# PCIE0_CORE_DBN_CFG_PCIE_CORE register map
Vendor: Texas Instruments
Registers are 32-bit, read-write, reset 0x0 unless marked. A register's access mark holds for its fields unless they carry their own. Offsets are as the file gives them; [hi:lo] are bit positions; lines under a group give offsets from that group; {n}, {i} and the like mark numbered series.

## PCIE0_CORE_DBN_CFG_PCIE_CORE (part 4 of 6)
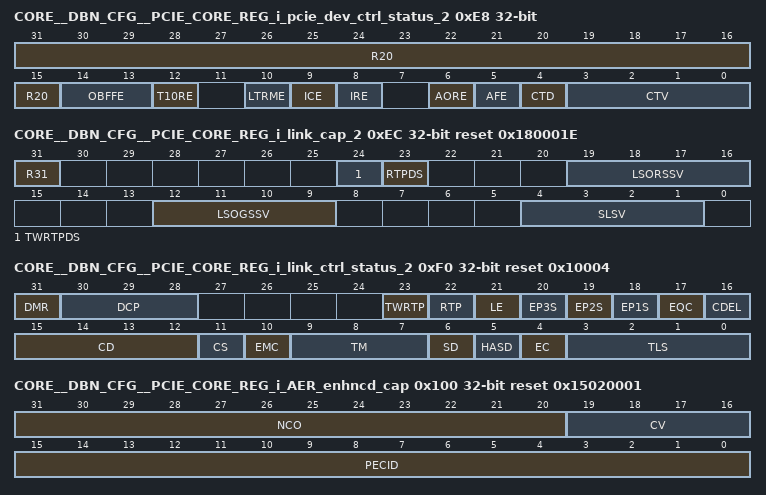
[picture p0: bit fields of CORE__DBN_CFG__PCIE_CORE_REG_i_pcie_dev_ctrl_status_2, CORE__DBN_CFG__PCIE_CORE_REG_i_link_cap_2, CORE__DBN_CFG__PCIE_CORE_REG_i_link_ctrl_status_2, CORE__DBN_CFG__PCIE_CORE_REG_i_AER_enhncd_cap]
0xE8 CORE__DBN_CFG__PCIE_CORE_REG_i_pcie_dev_ctrl_status_2 access per field
  [31:15] R20 ro
  [14:13] OBFFE rw — Enables the Optimized Buffer Flush/Fill [OBFF] capability in the device. Valid settings are 00 [disabled], 01 [Variation A], and 10 [Variation B].
  [12] T10RE ro — 10bit TAGs generation are not supported in this configuration.
  [10] LTRME rw — This must be set to 1 to enable the Latency Tolerance Reporting Mechanism. This bit is implemented only in PF 0. Its default value is 1, but can be modified from the local management bus. This bit is read-only in PF 1.
  [9] ICE rw — When this bit is 1, the RC is allowed to set the ID-based Ordering [IDO] Attribute bit in the Completions it generates.
  [8] IRE rw — When this bit is 1, the RC is allowed to set the ID-based Ordering [IDO] Attribute bit in the requests it generates.
  [6] AORE ro — This bit must be set to enable the generation of Atomic Op Requests. If the client logic attempts to send an Atomic Op when this bit is not set, logic in the Controller will nullify the TLP on its way to the link.
  [5] AFE rw — A 1 in this filed indicates that the port treats fields 7:0 of the ID as function number while converting a Type 1 config packet to type 0 config packet.
  [4] CTD rw — Setting this bit disables the Completion Timeout in the device.
  [3:0] CTV rw — Specifies the Completion Timeout value for the device. Allowable values are 0101 [sub-range 1] and 0110 [sub-range 2]. The corresponding timeout values are stored in the local management register's Completion Timeout Interval Registers 0 and 1, respectively. Value of 0 selects completion timeout from Completion-Timeout-Interval-Registers-0 in local management register.
0xEC CORE__DBN_CFG__PCIE_CORE_REG_i_link_cap_2 ro reset 0x180001E
  [31] R31 — Indicates support for the optional Device Readiness Status [DRS] capability. This capability is currently not supported in the Controller.
  [24] TWRTPDS — When set to 1b, this bit indicates that the associated Port supports detection and reporting of two Retimers presence. This bit is valid for both Downstream Ports and Upstream Ports.
  [23] RTPDS — When set to 1b, this bit indicates that the associated Port supports detection and reporting of Retimer presence. This bit is valid for both Downstream Ports and Upstream Ports.
  [19:16] LSORSSV — If this field is non-zero, it indicates that the Port, when operating at the indicated speed[s] supports SRIS and also supports receiving SKP OS at the rate defined for SRNS while running in SRIS.
  [12:9] LSOGSSV — If this field is non-zero, it indicates that the Port, when operating at the indicated speed[s] supports SRIS and also supports software control of the SKP Ordered Set transmission scheduling rate.
  [4:1] SLSV — This field indicates the supported link speeds of the Controller. For each bit, a value of 1 indicates that the corresponding link speed is supported, while a value of 0 indicates that the corresponding speed is not supported. The bits corresponding to various link speeds are: Bit 1 = Link Speed 2.5 GT/s, Bit 2 = Link Speed 5 GT/s, Bit 3 = Link Speed 8 GT/s, Bit 4 = Link Speed 16 GT/s. This field is hardwired to 0001 [2.5 GT/s] when the PCIE_GENERATION_SEL strap pins of the Controller are set to 0, 0011 [2.5 and 5 GT/s] when the strap is set to 1, and 0111 [2.5, 5, and 8 GT/s] when the strap pin is set to 10, and 1111 [2.5, 5, 8 and 16 GT/s] when the strap pin is set to 11.
0xF0 CORE__DBN_CFG__PCIE_CORE_REG_i_fc_init_delay_reg reset 0x64
  [15:0] FCINITDLY — Delay between successive sets of P, NP, CPL FC_INIT DLLP transmissions for VCx.
0xF0 CORE__DBN_CFG__PCIE_CORE_REG_i_link_ctrl_status_2 access not given reset 0x10004
  [31] DMR ro — DRS is not supported by the Controller and hence this field is not implemented.
  [30:28] DCP ro — DRS is not supported by the Controller and hence this field is not implemented.
  [23] TWRTP ro — When set to 1b, this bit indicates that two Retimers were present during the most recent Link negotiation.
  [22] RTP ro — When set to 1b, this bit indicates that a Retimer was present during the most recent Link negotiation.
  [21] LE — When the Controller [RP] receives an 8GTs equalization request from an Upstream Port the Controller internally sets this bit to 1. [i.e. when RP is in the Recovery.RcvrCfg state and receives 8 consecutive TS2 Ordered Sets with the Request Equalization bit set to 1b] The LOCAL_INTERRUPT output is also asserted if Link Equalization Request Interrupt Enable is enabled. (access R/W1TC)
  [20] EP3S ro — This bit, when set to 1, indicates that the Phase 3 of the Transmitter Equalization procedure has completed successfully. STICKY
  [19] EP2S ro — This bit, when set to 1, indicates that the Phase 2 of the Transmitter Equalization procedure has completed successfully. STICKY
  [18] EP1S ro — This bit, when set to 1, indicates that the Phase 1 of the Transmitter Equalization procedure has completed successfully. STICKY
  [17] EQC ro — This bit, when set to 1, indicates that the Transmitter Equalization procedure has completed. STICKY
  [16] CDEL ro — This status bit indicates the current operating de-emphasis level of the transmitter [0 = -6dB, 1 = -3.5dB].
  [15:12] CD rw — This bit sets the de-emphasis level [for 5 GT/s operation] or the Transmitter Preset level [for 8 GT/s or 16 GT/s operation] when the LTSSM enters the Polling.Compliance state because of software setting the Enter Compliance bit in this register. It is used only when the link is running at 5 GT/s or 8 GT/s or 16 GT/s. At 5 GT/s, the only valid setting are 0 [-6 dB] and 1 [-3.5 dB]. STICKY
  [11] CS rw — When this bit is set to 1, the device will transmit SKP ordered sets between compliance patterns. STICKY
  [10] EMC rw — This field is intended for debug and compliance testing purposes only. If this bit is set to 1, the device will transmit the Modified Compliance Pattern when the LTSSM enters the Polling.Compliance substate. STICKY
  [9:7] TM rw — This field is intended for debug and compliance testing purposes only. It controls the non-deemphasized voltage level at the transmitter outputs. Its encodings are: 000 = Normal operating range, 001 = 800 - 1200 mV for full swing and 400 - 700 mV for half swing, 010 - 111 = See PCI Express Base Specification 2.0. This field is reset to 0 when th LTSSM enters the Polling.Configuration substate during link training. STICKY.
  [6] SD rw — This bit selects the de-emphasis level when the Controller is operating at 5 GT/s [0 = -6 dB, 1 = -3.5 dB].
  [5] HASD rw — When this bit is set, the LTSSM is prevented from changing the operating speed of the link, other than reducing the speed to correct unreliable operation of the link. STICKY
  [4] EC rw — This bit is used to force the Endpoint device to enter the Compliance mode. Software sets this bit to 1 and initiates a hot reset to force the device into the Compliance mode. The target speed for the Compliance mode is determined by the Target Link Speed field of this register. STICKY.
  [3:0] TLS rw — This field sets the target speed when the software forces the link into Compliance mode by setting the Enter Compliance bit in this register [0001 = 2.5 GT/s, 0010 = 5 GT/s, 0100 = 8 GT/s,1000 = 16 GT/s]. The default value of this field is 0001 [2.5 GT/s] when the PCIE_GENERATION_SEL[1:0] strap pins of the Controller are set to 0, 0010 [5 GT/s] when the strap is set to 1, and 0011 [8 GT/s] when the strap pin is set to 10 , and 0100 [16 GT/s] when the strap pin is set to 11. STICKY.
{0x100+4i} CORE__DBN_CFG__PCIE_CORE_REG_i_shdw_hdr_log_{i}_reg (i=0..3)
  [31:0] SHDW_HDR_LOG_{i} — The value here will be reflected in the target function's header log register when f/w sets any bit in the the shadow error register. If the header log is already set in the function's AER space, the value here may not get written and a header log overflow bit would get set. This register holds [{32i+31}:{32i}] value of the TLP header.
0x100 CORE__DBN_CFG__PCIE_CORE_REG_i_AER_enhncd_cap ro reset 0x15020001
  [31:20] NCO — Indicates offset to the next PCI Express capability structure. The default next pointer value is dynamic and is dependent on whether the strap or LMI bits are set.
  [19:16] CV — Specifies the SIG assigned value for the version of the capability structure. This field is set by default to 4'h2.
  [15:0] PECID — This field is hardwired to the Capability ID assigned by PCI SIG to the PCI Express AER Extended Capability Structure [0001 hex].
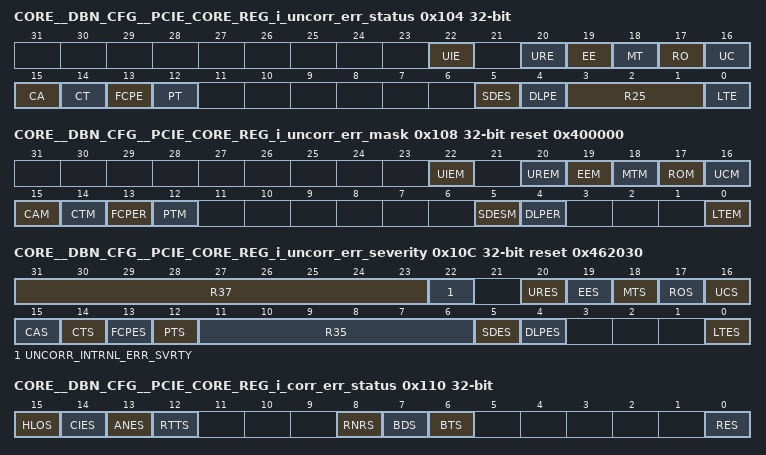
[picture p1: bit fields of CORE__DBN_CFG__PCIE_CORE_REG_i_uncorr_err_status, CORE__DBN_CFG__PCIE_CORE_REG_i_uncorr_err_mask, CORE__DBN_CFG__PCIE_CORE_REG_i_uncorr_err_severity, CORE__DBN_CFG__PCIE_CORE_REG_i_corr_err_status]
0x104 CORE__DBN_CFG__PCIE_CORE_REG_i_uncorr_err_status access not given
  [22] UIE — This bit is set when the Controller has detected an internal uncorrectable error [HAL parity error or an uncorrectable ECC error while reading from any of the RAMs]. This bit is also set in response to the client signaling an internal error through the input UNCORRECTABLE_ERROR_IN. This error is considered fatal by default. (access R/W1TC)
  [20] URE — This bit is set when the Controller has received a request from the link that it does not support. This error is not Function-specific. This error is considered non-fatal by default, except for the special case outlined in PCI Express Base Specification 2.0. The header of the received request that caused the error is logged in the Header Log Registers. (access R/W1TC)
  [19] EE — This bit is set when the Controller has detected an ECRC error in a received TLP. (access R/W1TC)
  [18] MT — This bit is set when the Controller receives a malformed TLP from the link. This error is considered fatal by default. The header of the received TLP with error is logged in the Header Log Registers. (access R/W1TC)
  [17] RO — This bit is set when the Controller receives a TLP in violation of the receive credit currently available. (access R/W1TC)
  [16] UC — This bit is set when the Controller has received an unexpected Completion packet from the link. (access R/W1TC)
  [15] CA — This bit is set when the Controller has returned the Completer Abort [CA] status to a request received from the link. This error is considered non-fatal by default, except for the special cases outlined in PCI Express Base Specification 2.0. The header of the received request that caused the error is logged in the Header Log Registers. (access R/W1TC)
  [14] CT — This bit is set when the completion timer associated with an outstanding request times out. This error is considered non-fatal by default. (access R/W1TC)
  [13] FCPE — This bit is set when certain violations of the flow control protocol are detected by the Controller. (access R/W1TC)
  [12] PT — This bit is set when the Controller receives a poisoned TLP from the link. This error is considered non-fatal by default. The header of the received TLP with error is logged in the Header Log Registers. (access R/W1TC)
  [5] SDES — This error status indicates Link up to Link down event. So Status bit is set upon LINK_DOWN_RESET_OUT event. This field is applicable to RC only and not for EP as per PCIE-spec. (access R/W1TC)
  [4] DLPE — This bit is set when the Controller receives an Ack or Nak DLLP whose sequence does not correspond to that of an unacknowledged TLP or that of the last acknowledged TLP [for details, refer to the PCI Express Base Specifications]. (access R/W1TC)
  [3:1] R25 ro
  [0] LTE — This error indicates that link training is not successful and transition back to detect state. This Status bit is set on any LTSSM transition from Configuration to Detect or Recovery to Detect. This field is applicable to RC only and not for EP as per PCIE-spec. (access R/W1TC)
0x108 CORE__DBN_CFG__PCIE_CORE_REG_i_uncorr_err_mask reset 0x400000
  [22] UIEM — This bit is set to mask the reporting of internal errors. STICKY.
  [20] UREM — This bit is set to mask the reporting of unexpected requests received from the link. STICKY.
  [19] EEM — This bit is set to mask the reporting of ECRC errors. STICKY.
  [18] MTM — This bit is set to mask the reporting of malformed TLPs received from the link. STICKY.
  [17] ROM — This bit is set to mask the reporting of violations of receive credit. STICKY.
  [16] UCM — This bit is set to mask the reporting of unexpected Completions received by the Controller. STICKY.
  [15] CAM — This bit is set to mask the reporting of the Controller sending a Completer Abort. STICKY.
  [14] CTM — This bit is set to mask the reporting of Completion Timeouts. STICKY.
  [13] FCPER — This bit is set to mask the reporting of Flow Control Protocol Errors. STICKY.
  [12] PTM — This bit is set to mask the reporting of a Poisoned TLP. STICKY.
  [5] SDESM — This bit is set to mask the reporting of Surprise Down Error Status Mask. STICKY. This field is applicable to RC only and not for EP as per PCIE-spec.
  [4] DLPER — This bit is set to mask the reporting of Data Link Protocol Errors. STICKY.
  [0] LTEM — This bit is set to mask the reporting of Link Training Error Mask. STICKY. This field is applicable to RC only and not for EP as per PCIE-spec.
0x10C CORE__DBN_CFG__PCIE_CORE_REG_i_uncorr_err_severity access per field reset 0x462030
  [31:23] R37 ro
  [22] UNCORR_INTRNL_ERR_SVRTY rw — Severity of internal errors [0 = Non-Fatal, 1 = Fatal].
  [20] URES rw — Severity of unexpected requests received from the link [0 = Non-Fatal, 1 = Fatal]. STICKY.
  [19] EES rw — Severity of ECRC errors [0 = Non-Fatal, 1 = Fatal]. STICKY.
  [18] MTS rw — Severity of malformed TLPs received from the link [0 = Non-Fatal, 1 = Fatal]. STICKY.
  [17] ROS rw — Severity of receive credit violations [0 = Non-Fatal, 1 = Fatal]. STICKY.
  [16] UCS rw — Severity of unexpected Completions received by the Controller [0 = Non-Fatal, 1 = Fatal]. STICKY.
  [15] CAS rw — Severity of sending a Completer Abort [0 = Non-Fatal, 1 = Fatal]. STICKY.
  [14] CTS rw — Severity of Completion Timeouts [0 = Non-Fatal, 1 = Fatal]. STICKY.
  [13] FCPES rw — Severity of a Flow Control Protocol Error [0 = Non-Fatal, 1 = Fatal]. STICKY.
  [12] PTS rw — Severity of a Poisoned TLP error [0 = Non-Fatal, 1 = Fatal]. STICKY.
  [11:6] R35 ro
  [5] SDES rw — surprise down error severity [0 = Non-Fatal, 1 = Fatal]. STICKY. This field is applicable to RC only and not for EP as per PCIE-spec.
  [4] DLPES rw — Severity of Data Link Protocol Errors [0 = Non-Fatal, 1 = Fatal]. STICKY.
  [0] LTES rw — Severity of Link Training Error [0 = Non-Fatal, 1 = Fatal]. STICKY. This field is applicable to RC only and not for EP as per PCIE-spec.
0x110 CORE__DBN_CFG__PCIE_CORE_REG_i_shdw_func_num_reg
  [7:0] SHDW_FUNC_NUM — The value here will be the target function number when f/w sets any bit in the shadow error register.
0x110 CORE__DBN_CFG__PCIE_CORE_REG_i_corr_err_status access not given
  [15] HLOS — This bit is set on a Header Log Register overflow, that is, when the header could not be logged in the Header Log Register because it is occupied by a previous header. (access R/W1TC)
  [14] CIES — This bit is set when the Controller has detected an internal correctable error condition [a correctable ECC error while reading from any of the RAMs]. This bit is also set in response to the client signaling an internal error through the input CORRECTABLE_ERROR_IN. (access R/W1TC)
  [13] ANES — This bit is set when an uncorrectable error occurs, which is determined to belong to one of the special cases described in the PCI Express Base Specification 2.0. This causes the Controller to assert the CORRECTABLE_ERROR_OUT output in place of NON_FATAL_ERROR_OUT. (access R/W1TC)
  [12] RTTS — This bit is set when the replay timer in the Data Link Layer of the Controller times out, causing the Controller to re-transmit a TLP. (access R/W1TC)
  [8] RNRS — This bit is set when the replay count rolls over after three re-transmissions of a TLP at the Data Link Layer of the Controller. (access R/W1TC)
  [7] BDS — This bit is set when an LCRC error is detected in a received DLLP, and no errors were detected by the Physical Layer. (access R/W1TC)
  [6] BTS — This bit is set when an error is detected in a received TLP by the Data Link Layer of the Controller the conditions causing this error are [1] an LCRC error, [2] the packet terminates with EDB symbol, but its LCRC field does not equal the inverted value of the calculated CRC. (access R/W1TC)
  [0] RES — This bit is set when an error is detected in the receive side of the Physical Layer of the Controller [e.g. an 8b10b decode error]. (access R/W1TC)
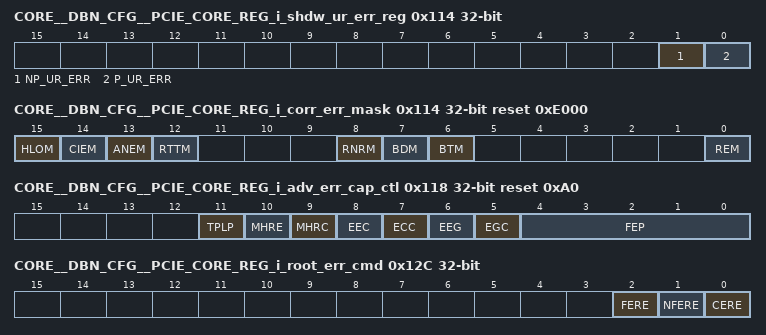
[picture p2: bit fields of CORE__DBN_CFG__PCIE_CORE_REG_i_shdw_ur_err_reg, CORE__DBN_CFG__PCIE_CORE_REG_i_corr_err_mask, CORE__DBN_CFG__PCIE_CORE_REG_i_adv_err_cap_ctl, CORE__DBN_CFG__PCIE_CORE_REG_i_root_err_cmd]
0x114 CORE__DBN_CFG__PCIE_CORE_REG_i_shdw_ur_err_reg wo
  [1] NP_UR_ERR — If this bit is set, the corresponding non-posted UR error bits will be set in the AER and device status registers of the target function.
  [0] P_UR_ERR — If this bit is set, the corresponding posted UR error bits will be set in the AER and device status registers of the target function.
0x114 CORE__DBN_CFG__PCIE_CORE_REG_i_corr_err_mask reset 0xE000
  [15] HLOM — This bit, when set, masks the reporting of an error in response to a Header Log register overflow. STICKY.
  [14] CIEM — This bit, when set, masks the reporting of an error in response to a corrected internal error condition. STICKY.
  [13] ANEM — This bit, when set, masks the reporting of an error in response to an uncorrectable error occurence, which is determined to belong to one of the special cases in the PCI Express Base Specification 2.0. STICKY.
  [12] RTTM — This bit, when set, masks the reporting of an error in response to a Replay Timer timeout event. STICKY.
  [8] RNRM — This bit, when set, masks the reporting of an error in response to a Replay Number Rollover event. STICKY.
  [7] BDM — This bit, when set, masks the reporting of an error in response to a 'Bad DLLP' received. STICKY.
  [6] BTM — This bit,when set, masks the reporting of an error in response to a 'Bad TLP' received. STICKY.
  [0] REM — This bit, when set, masks the reporting of Physical Layer errors. STICKY.
0x118 CORE__DBN_CFG__PCIE_CORE_REG_i_adv_err_cap_ctl access per field reset 0xA0
  [11] TPLP ro — If Set and the First Error Pointer is valid, indicates that the TLP Prefix Log register contains valid information. If Clear or if First Error Pointer is invalid, the TLP Prefix Log register is undefined. Default value of this bit is 0. This bit is RsvdP if the End-End TLP Prefix Supported bit is CIf Set and the First Error Pointer is valid, indicates that the TLP Prefix Log register contains valid information. If Clear or if First Error Pointer is invalid, the TLP Prefix Log register is undefined.
  [10] MHRE ro — Setting this bit enables the RC to log multiple error headers in its Header Log Registers. It is hardwired to 0.
  [9] MHRC ro — This bit is set when the RC has the capability to log more than one error header in its Header Log Registers. It is hardwired to 0.
  [8] EEC rw — Setting this bit enables ECRC checking on the receive side of the Controller. This bit is writable from the local management bus. STICKY.
  [7] ECC ro — This read-only bit indicates to the software that the device is capable of checking ECRC in packets received from the link.
  [6] EEG rw — Setting this bit enables the ECRC generation on the transmit side of the Controller. This bit is writable from the local management bus. STICKY.
  [5] EGC ro — This read-only bit indicates to the software that the device is capable of generating ECRC in packets transmitted on the link.
  [4:0] FEP ro — This is a 5-bit pointer to the bit position in the Uncorrectable Error Status Register corresponding to the error that was detected first. When there are multiple bits set in the Uncorrectable Error Status Register, this field informs the software which error was observed first. To prevent the field from being overwritten before the software is able to read it, this field is not updated while the status bit it points to in the Uncorrectable Error Status Register remains set. After the software clears this status bit, a subsequent error condition that sets any bit in the Uncorrectable Error Status Register will update the First Error Pointer. Any uncorrectable error type, including the special cases where the error is reported using an ERR_COR message, will set the First Error Pointer [assuming the software has reset the error pointed by it in the Uncorrectable Error Status Register]. STICKY.
0x11C CORE__DBN_CFG__PCIE_CORE_REG_i_hdr_log_0 ro
  [31:0] HD0 — First Dword of captured TLP header. STICKY.
0x120 CORE__DBN_CFG__PCIE_CORE_REG_i_hdr_log_1 ro
  [31:0] HD1 — Second Dword of captured TLP header. STICKY.
0x124 CORE__DBN_CFG__PCIE_CORE_REG_i_hdr_log_2 ro
  [31:0] HD2 — Third Dword of captured TLP header. STICKY.
0x128 CORE__DBN_CFG__PCIE_CORE_REG_i_hdr_log_3 ro
  [31:0] HD3 — Fourth Dword of captured TLP header. STICKY.
0x12C CORE__DBN_CFG__PCIE_CORE_REG_i_root_err_cmd
  [2] FERE — If this bit is set, the Controller will active its FATAL_ERROR_OUT output in response to an error message received from the link.
  [1] NFERE — If this bit is set, the Controller will active its NON_FATAL_ERROR_OUT output in response to an error message received from the link.
  [0] CERE — If this bit is set, the Controller will active its CORRECTABLE_ERROR_OUT output in response to an error message received from the link.
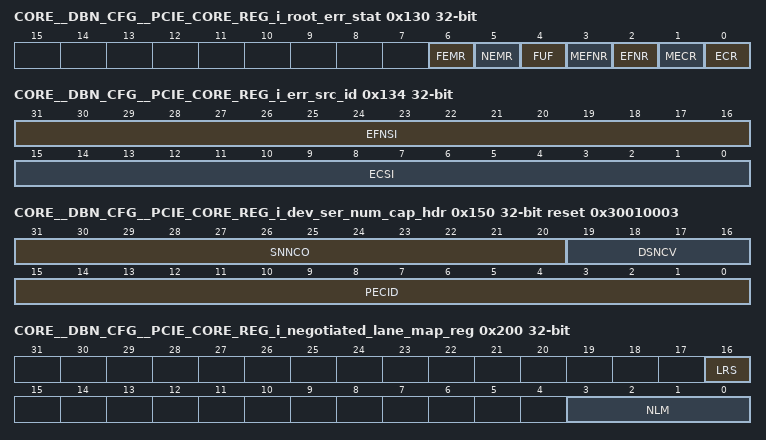
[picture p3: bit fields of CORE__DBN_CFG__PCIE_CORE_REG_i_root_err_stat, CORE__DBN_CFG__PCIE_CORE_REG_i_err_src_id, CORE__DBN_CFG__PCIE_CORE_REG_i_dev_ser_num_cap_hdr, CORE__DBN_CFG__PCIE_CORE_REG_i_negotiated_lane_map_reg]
0x130 CORE__DBN_CFG__PCIE_CORE_REG_i_root_err_stat access not given
  [6] FEMR — This bit, when set, indicates that the RC has received one or more Fatal error messages from the link. STICKY (access R/W1TC)
  [5] NEMR — This bit, when set, indicates that the RC has received one or more Non-Fatal error messages from the link. STICKY (access R/W1TC)
  [4] FUF — This bit, when set, indicates that the first Uncorrectable error message received was for a Fatal error. STICKY (access R/W1TC)
  [3] MEFNR — This bit is set when the RC receives either a Fatal or Non-Fatal error message from the link, and the ERR_FATAL/NONFATAL Received bit is already set. STICKY (access R/W1TC)
  [2] EFNR — This bit is set when the RC receives either a Fatal or Non-Fatal error message from the link. STICKY (access R/W1TC)
  [1] MECR — This bit is set when the RC receives a Correctable error message from the link, if the ERR_COR received bit is already set. STICKY (access R/W1TC)
  [0] ECR — This bit is set when the RC receives a Correctable error message from the link. STICKY (access R/W1TC)
0x134 CORE__DBN_CFG__PCIE_CORE_REG_i_err_src_id ro
  [31:16] EFNSI — This field captures and stores the Requester ID from an ERR_FATAL or ERROR_NONFATAL message received by the RC, if the ERR_FATAL or NONFATAL Received bit was not set at the time the message was received. STICKY
  [15:0] ECSI — This field captures and stores the Requester ID from an ERR_COR message received by the RC, if the ERR_COR bit was not set at the time the message was received. STICKY
0x138 CORE__DBN_CFG__PCIE_CORE_REG_i_tlp_pre_log_0 ro
  [31:0] HD1 — First TLP Prefix of captured TLP STICKY.
0x140 CORE__DBN_CFG__PCIE_CORE_REG_i_pm_clk_frequency_reg reset 0x19
  [7:0] PMCLKFRQ — This field specifies the PM_CLK Frequency selected. The encoding is described below: 000000: Reserved 000001: Reserved 000010: PM_CLK is 2 MHz 000011: PM_CLK is 3 MHz 000100: PM_CLK is 4 MHz 000101: PM_CLK is 5 MHz .. 111010: PM_CLK is 58 MHz 111011: PM_CLK is 59 MHz 111100: PM_CLK is 60 MHz 111101 : Reserved 111110 : Reserved 111111 : Reserved .
{0x140+4i} CORE__DBN_CFG__PCIE_CORE_REG_i_debug_dllp_count_gen{i}_reg ro (i=1..4)
  [31:0] DLLPCNT{i} — Reflects the total number of DLLPs received by the Controller at GEN{i} speed.
0x150 CORE__DBN_CFG__PCIE_CORE_REG_i_dev_ser_num_cap_hdr ro reset 0x30010003
  [31:20] SNNCO — Indicates offset to the next PCI Express capability structure. The default next pointer value is dynamic and is dependent on whether the strap or LMI bits are set.
  [19:16] DSNCV — Specifies the SIG assigned value for the version of the capability structure. This field is set by default to 1, but can be modified from the local management bus by writing into Function 0 from the local management bus.
  [15:0] PECID — This field is hardwired to the Capability ID assigned by PCI SIG to the PCI Express Device Serial Number Capability [0001 hex].
0x154 CORE__DBN_CFG__PCIE_CORE_REG_i_dev_ser_num_0 ro
  [31:0] DSND0 — This field contains the first 32 bits of the device's serial number. This field can be written from the APB bus by setting [21] bit high of the pcie_mgmt_APB_ADDR during a local management register write.
0x158 CORE__DBN_CFG__PCIE_CORE_REG_i_vendor_defined_message_tag_reg
  [7:0] VDMTAG — The Controller will use the tag programed in this register for all Outbound Vendor Defined Messages.
0x158 CORE__DBN_CFG__PCIE_CORE_REG_i_dev_ser_num_1 ro
  [31:0] DSND1 — This field contains the last 32 bits of the device's serial number. This field can be written from the APB bus by setting [21] bit high of the pcie_mgmt_APB_ADDR during a local management register write.
0x200 CORE__DBN_CFG__PCIE_CORE_REG_i_negotiated_lane_map_reg ro
  [16] LRS — This bit set by the Controller at the end of link training if the LTSSM had to reverse the lane numbers to form the link.
  [3:0] NLM — Bit i of this field is set to 1 at the end of link training if Lane i is part of the PCIe link. The value of this field is valid only when the link is in L0 or L0s states.
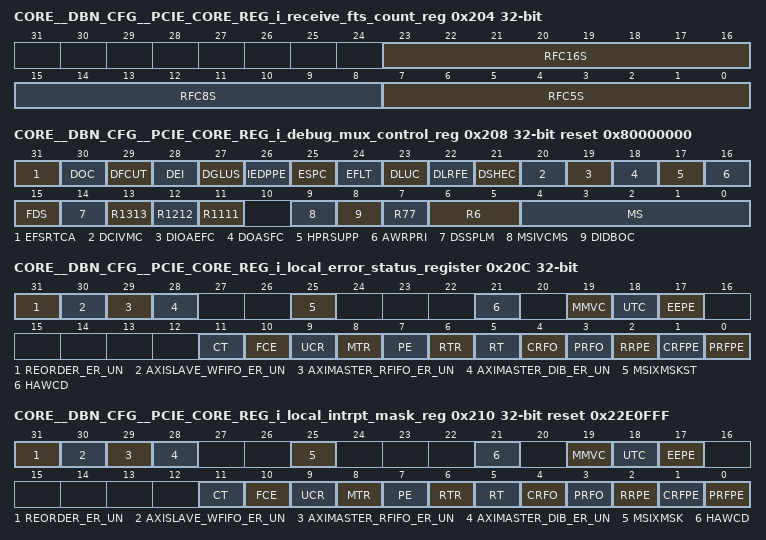
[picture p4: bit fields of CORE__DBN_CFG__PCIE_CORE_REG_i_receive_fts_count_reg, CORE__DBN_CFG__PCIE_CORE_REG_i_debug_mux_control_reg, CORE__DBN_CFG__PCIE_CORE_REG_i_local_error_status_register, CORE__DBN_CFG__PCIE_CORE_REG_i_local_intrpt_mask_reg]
0x204 CORE__DBN_CFG__PCIE_CORE_REG_i_receive_fts_count_reg ro
  [23:16] RFC16S — FTS count received from the other side during link training for use at the 16 GT/s link speed. The Controller transmits this many FTS sequences while exiting the L0S state, when operating at the 16 GT/s speed.
  [15:8] RFC8S — FTS count received from the other side during link training for use at the 8 GT/s link speed. The Controller transmits this many FTS sequences while exiting the L0S state, when operating at the 8 GT/s speed.
  [7:0] RFC5S — FTS count received from the other side during link training for use at the 5 GT/s link speed. The Controller transmits this many FTS sequences while exiting the L0S state, when operating at the 5 GT/s speed.
0x208 CORE__DBN_CFG__PCIE_CORE_REG_i_debug_mux_control_reg access per field reset 0x80000000
  [31] EFSRTCA rw — Setting this bit to 0 causes all the enabled Functions to report an error when a Type-1 configuration access is received by the Controller, targeted at any Function. Setting it to 1 limits the error reporting to the type-0 Function whose number matches with the Function number specified in the request. If the Function number in the request refers to an unimplemented or disabled Function, all enabled Functions report the error regardless of the setting of this bit.
  [30] DOC rw — Setting this bit to 1 disables the ordering check in the Controller between Completions and Posted requests received from the link.
  [29] DFCUT rw — When this bit is 0, the Controller will time out and re-train the link when no Flow Control Update DLLPs are received from the link within an interval of 128 us. Setting this bit to 1 disables this timeout. When the advertised receive credit of the link partner is infinity for the header and payload of all credit types, this timeout is always suppressed. The setting of this bit has no effect in this case. This bit should not be set during normal operation, but is useful for testing.
  [28] DEI rw — Setting this bit to 1 disables the inferring of electrical idle in the L0 state. Electrical idle is inferred when no flow control updates and no SKP sequences are received within an interval of 128 us. This bit should not be set during normal operation, but is useful for testing.
  [27] DGLUS rw — Setting this bit to 1 disables the update of the LFSRs in the Gen3 descramblers of the Controller, from the values received in SKP sequences. This bit should not be set during normal operation, but is useful for testing.
  [26] IEDPPE rw — When set to 1, this bit inverts the parity bits generated by the Controller for end-to-end data protection. This will result in the inversion of parity bits for data payloads delivered through the HAL Target Interface request descriptor. This bit is to be used for diagnostics only, and should not be set during normal operation.
  [25] ESPC rw — When this bit is set to 1, the Controller will capture the Slot Power Limit Value and Slot Power Limit Scale parameters from a Set_Slot_Power_Limit message received in the Device Capabilities Register. When this bit is 0, the capture is disabled. This bit is valid only when the Controller is configured as an EndPoint. It has no effect when the Controller is a Root Complex.
  [24] EFLT rw — This bit is provided to shorten the link training time to facilitate fast simulation of the design, especially at the gate level. Enabling this bit has the following effects: 1. The 1 ms, 2 ms, 12 ms, 24 ms, 32 ms and 48 ms timeout intervals in the LTSSM are shortened by a factor of 500. 2. In the Polling.Active state of the LTSSM, only 16 training sequences are required to be transmitted [Instead of 1024] to make the transition to the Configuration state. This bit should not be set during normal operation of the Controller.
  [23] DLUC rw — The user may set this bit to turn off the link upconfigure capability of the Controller. Setting this bit prevents the Controller from advertising the link upconfigure capability in training sequences transmitted in the Configuration.Complete state. In addition, setting this bit causes the Controller to put the unused lanes into Turn Off mode. When disable_link_upconfigure_capability==1: Controller drives PIPE_TX_ELEC_IDLE==1 AND PIPE_TX_COMPLIANCE==1 for the Unused upper lanes. The Unused upper lanes are put into Turn Off mode by the PHY as per PIPE specification. When disable_link_upconfigure_capability==0: Controller drives PIPE_TX_ELEC_IDLE==1 AND PIPE_TX_COMPLIANCE==0 for the Unused upper lanes. The Unused upper lanes are put into Electrical Idle by the PHY.
  [22] DLRFE rw — When this bit is 1, the Controller will not transition its LTSSM into the Recovery state when it detects a Framing Error at 8 GT/s or 16 GT/s speed [as defined in Section 4.2.2.3.3 of the PCIe Base Specification 3.0. This bit must normally be set to 0 so that a Framing Error will cause the LTSSM to enter Recovery. The setting of this bit has no effect on the operation of the Controller at 2.5 and 5 GT/s speeds.
  [21] DSHEC rw — When this bit is 0, the Controller will signal a framing error if it detects a sync header error in the received blocks at 8 GT/s or 16 GT/s speed [A 00 or 11 binary setting of the sync header on the received blocks in any lane constitutes a framing error]. Setting this bit to 1 suppresses this error check. This bit should normally be set to 0, as the sync header check is mandatory in the PCIe 3.0 Specifications.
  [20] DCIVMC rw — When this bit is 1, the Controller will not check for invalid message codes. This bit should normally set to 0, as the invalid message code checking is mandatory in the PCIe 3.0 specifications.
  [19] DIOAEFC rw — When this bit is 1, the Controller will not check for illegal OS after EDS as part of Gen3 Framing Error Checks. This bit should normally set to 0, as this is a mandatory Gen3 Framing Error check in the PCIe 3.0 specifications.
  [18] DOASFC rw — When this bit is 1, the Controller will not check for OS after SKIP OS as part of Gen3 Framing Error Checks. This bit should normally set to 0, as this is a mandatory Gen3 Framing Error check in the PCIe 3.0 specifications.
  [17] HPRSUPP rw — When this bit is 1, data path parity check is disabled on the TX side of the Controller.
  [16] AWRPRI rw — When this bit is 1, the AXI bridge places a write request on the HAL Master interface in preference over a read request if both AXI write and AXI read requests are available to be asserted on the same clock cycle.
  [15] FDS rw — Disable Scrambling/Descrambling in Gen1/Gen2.
  [14] DSSPLM rw — Disable sending Set Slot Power Limit Message if the Slot Capabilitied register is configured
  [13] R1313 ro
  [12] R1212 ro
  [11] R1111 rw — When this bit is 1, Disable Client TX MUX Completion and PNP request arbitartion,roundrobin priority logic added to prevent PNP requests from starving when completions are present
  [9] MSIVCMS rw — Sets the mode of generating MSI_VECTOR_COUNT output for all functions. 0 - MSI_VECTOR_COUNT always outputs the configured value of MSI Multiple Message Enable[2:0] register. 1 - MSI_VECTOR_COUNT outputs the lesser of the MSI Multiple Message Enable[2:0] and MSI Multiple Message Capable[2:0] This mode can be used to handle any programming error form the Host software.
  [8] DIDBOC rw — Setting this bit to 1 disables the ID Based Ordering check in the Controller between Completions and Posted requests received from the link.
  [7] R77 rw — This bit should be set to 0 for backward compatibility.
  [6:5] R6 ro
  [4:0] MS rw — Bits 4:3 select the module and bits 2:0 select the group of signals within the module that are driven on the debug bus. The assignments of signals on the debug outputs of the Controller are given in Appendix B.
0x20C CORE__DBN_CFG__PCIE_CORE_REG_i_local_error_status_register access not given
  [31] REORDER_ER_UN — This indicates an uncorrectbale axi slave reorder ram parity/ecc error (access R/W1TC)
  [30] AXISLAVE_WFIFO_ER_UN — This indicates an uncorrectbale axi slave write fifo ram parity/ecc error (access R/W1TC)
  [29] AXIMASTER_RFIFO_ER_UN — This indicates an uncorrectbale axi master write fifo ram parity/ecc error (access R/W1TC)
  [28] AXIMASTER_DIB_ER_UN — This indicates an uncorrectbale axi slave write fifo ram parity/ecc error (access R/W1TC)
  [25] MSIXMSKST — This interrupt status bit is used when MSIX Function Mask Enhanced Interrupt Enable bit is set to 0 by the User. This status bit indicates that the MSIX Function Mask bit of any function, PF or VF, was programmed or configured by Local Firmware Or Host SW. (access R/W1TC)
  [21] HAWCD — This interrupt status bit indicates that the Host toggled the Hardware Autonomous Width Change bit in the Link Control Register through a Config Write. Upon this interrupt, the Client firmware must read the Link Control Register to check the value set by Host in the Hardware Autonomous Width Change bit. The Host Software may disable autonomous width change by setting Hardware Autonomous Width Disable bit in the Link Control register. If disabled by the Host and if the Endpoint firmware had initiated an autonomous width downsizing prior to this interrupt, then the local Client firmware is responsible to upconfigure the Link to go to its full functional width by initiating the link_upconfigure_retrain_link within 1 ms of this interrupt. (access R/W1TC)
  [19] MMVC — This status bit is set whenever the MSI mask register value in the MSI capability register changes value in ANY of the functions in the controller (access R/W1TC)
  [18] UTC — Unmapped TC error. (access R/W1TC)
  [17] EEPE — The Controller detected an End to End Parity Error (access R/W1TC)
  [11] CT — A request timed out waiting for completion. (access R/W1TC)
  [10] FCE — An error was observed in the flow control advertisements from the other side. (access R/W1TC)
  [9] UCR — Unexpected Completion received from the link. (access R/W1TC)
  [8] MTR — Malformed TLP received from the link. (access R/W1TC)
  [7] PE — Phy error detected on receive side. This bit is set when an error is detected in the receive side of the Physical Layer of the Controller [e.g. a bit error or coding violation]. This bit is set upon any of the following errors: [1] PHY reported 8B10B error, Disparity Error, Elastic Buffer Overflow Error, Underflow Error [2] GEN3 TLP, DLLP Framing Errors [3] OS Block Received Without EDS [4] Data Block Received After EDS [5] Illegal OS Block After EDS [6] OS Block Received After SKIP OS [7] OS Block Received After SDS [8] Sync Header Error [9] Loss of Gen3 Block Alignment This error is not Function-specific.. (access R/W1TC)
  [6] RTR — Replay timer rolled over after 4 transmissions of the same TLP. (access R/W1TC)
  [5] RT — Replay timer timed out (access R/W1TC)
  [4] CRFO — Overflow occurred in the Completion Receive FIFO. (access R/W1TC)
  [3] PRFO — Overflow occurred in the PNP Receive FIFO. (access R/W1TC)
  [2] RRPE — Parity error detected while reading from Replay Buffer RAM. (access R/W1TC)
  [1] CRFPE — Parity error detected while reading from the Completion Receive FIFO RAM. (access R/W1TC)
  [0] PRFPE — Parity error detected while reading from the PNP Receive FIFO RAM. (access R/W1TC)
0x210 CORE__DBN_CFG__PCIE_CORE_REG_i_local_intrpt_mask_reg reset 0x22E0FFF
  [31] REORDER_ER_UN — mask for uncorrectbale axi slave reorder ram parity/ecc error
  [30] AXISLAVE_WFIFO_ER_UN — mask for uncorrectbale axi slave write fifo ram parity/ecc error
  [29] AXIMASTER_RFIFO_ER_UN — mask for uncorrectbale axi master write fifo ram parity/ecc error
  [28] AXIMASTER_DIB_ER_UN — mask for uncorrectbale axi slave write fifo ram parity/ecc error
  [25] MSIXMSK — This bit is used to mask interrupt that indicates that the MSIX Function Mask bit of any function, PF or VF, was programmed or configured by Local Firmware Or Host SW.
  [21] HAWCD — This bit is used to mask interrupt that indicates that the Host toggled the Hardware Autonomous Width Change in the Endpoint Link Control Register through a Config Write.
  [19] MMVC — MSI mask register value in the MSI capability register changes value in ANY of the functions in the controller
  [18] UTC — Unmapped TC error
  [17] EEPE — The Controller detected an End to End Parity Error
  [11] CT — A request timed out waiting for completion.
  [10] FCE — An error was observed in the flow control advertisements from the other side.
  [9] UCR — Unexpected Completion received from the link.
  [8] MTR — Malformed TLP received from the link.
  [7] PE — Phy error detected on receive side.
  [6] RTR — Replay timer rolled over after 4 transmissions of the same TLP.
  [5] RT — Replay timer timed out
  [4] CRFO — Overflow occurred in the Completion Receive FIFO.
  [3] PRFO — Overflow occurred in the PNP Receive FIFO.
  [2] RRPE — Parity error detected while reading from Replay Buffer RAM.
  [1] CRFPE — Parity error detected while reading from the Completion Receive FIFO RAM.
  [0] PRFPE — Parity error detected while reading from the PNP Receive FIFO RAM.
0x214 CORE__DBN_CFG__PCIE_CORE_REG_i_lcrc_err_count_reg access not given
  [15:0] LEC — Number of TLPs received with LCRC errors. (access R/W1TC)
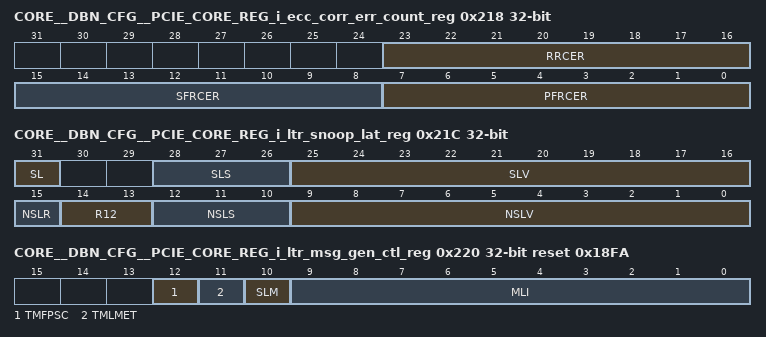
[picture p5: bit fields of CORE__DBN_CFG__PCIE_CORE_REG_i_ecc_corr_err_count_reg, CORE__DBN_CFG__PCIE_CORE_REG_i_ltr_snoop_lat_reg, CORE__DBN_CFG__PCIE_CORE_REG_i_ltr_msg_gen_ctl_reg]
0x218 CORE__DBN_CFG__PCIE_CORE_REG_i_ecc_corr_err_count_reg access not given
  [23:16] RRCER — Number of correctable errors detected while reading from the Replay Buffer RAM. This is an 8-bit saturating counter that can be cleared by writing all 1's into it. (access R/W1TC)
  [15:8] SFRCER — Number of correctable errors detected while reading from the SC FIFO RAM. This is an 8-bit saturating counter that can be cleared by writing all 1's into it. (access R/W1TC)
  [7:0] PFRCER — Number of correctable errors detected while reading from the PNP FIFO RAM. This is an 8-bit saturating counter that can be cleared by writing all 1's into it. (access R/W1TC)
0x21C CORE__DBN_CFG__PCIE_CORE_REG_i_ltr_snoop_lat_reg access per field
  [31] SL rw — The client software must set this bit to 1 to set the Snoop Latency Requirement bit in the LTR message to be sent.
  [28:26] SLS rw — The client software must program this field with the value to be sent in the Snoop Latency Scale field of the LTR message.
  [25:16] SLV rw — The client software must program this field with the value to be sent in the Snoop Latency Value field of the LTR message.
  [15] NSLR rw — The client software must set this bit to 1 to set the No-Snoop Latency Requirement bit in the LTR message to be sent.
  [14:13] R12 ro
  [12:10] NSLS rw — The client software must program this field with the value to be sent in the No-Snoop Latency Scale field of the LTR message.
  [9:0] NSLV rw — The client software must program this field with the value to be sent in the No-Snoop Latency Value field of the LTR message.
0x220 CORE__DBN_CFG__PCIE_CORE_REG_i_ltr_msg_gen_ctl_reg access per field reset 0x18FA
  [12] TMFPSC rw — When this bit is set to 1, the Controller will automatically transmit an LTR message when all the Functions in the Controller have transitioned to a non-D0 power state, provided that the following conditions are both true: 1. The Controller sent at least one LTR message since the Data Link layer last transitioned from down to up state. 2. The most recent LTR message transmitted by the Controller had as least one of the Requirement bits set. The Controller will set the Requirement bits in this LTR message to 0. When this bit 12 is 0, the Controller will not, by itself, send any LTR messages in response to Function Power State changes. Client logic may monitor the FUNCTION_POWER_STATE outputs of the Controller and transmit LTR messages through the master interface, in response to changes in their states.
  [11] TMLMET rw — When this bit is set to 1, the Controller will automatically transmit an LTR message whenever the LTR Mechanism Enable bit in the Device Control 2 Register changes from 0 to 1, with the parameters specified in the LTR Snoop/No-Snoop Latency Register. When this bit is 1, the Controller will also transmit an LTR message whenever the LTR Mechanism Enable bit is cleared, if the following conditions are both true: 1. The Controller sent at least one LTR message since the LTR Mechanism Enable bit was last set. 2. The most recent LTR message transmitted by the Controller had as least one of the Requirement bits set. The Controller will set the Requirement bits in this LTR message to 0. When this bit 11 is 0, the Controller will not, by itself, send any LTR messages in response to state changes of the LTR Mechanism Enable bit. Client logic may monitor the state of the LTR_MECHANISM_ ENABLE output of the Controller and transmit LTR messages through the master interface, in response to its state changes.
  [10] SLM ro — Setting this bit causes the Controller to transmit an LTR message with the parameters specified in the LTR Snoop/No-Snoop Latency Register [Section 8.4.2.9]. This bit is cleared by the Controller on transmitting the LTR message, and stays set until then. Client software must read this register and verify that this bit is 0 before setting it again to send a new message. This field becomes writable when LTR mechanism is enabled in device control-2 register.
  [9:0] MLI rw — This field specifies the minimum spacing between LTR messages transmitted by the Controller in units of microseconds. The PCI Express Specifications recommend sending no more than two LTR messages within a 500 microsecond interval. The Controller will wait for the minimum delay specified by this field after sending an LTR message, before transmitting a new LTR message. NOTE: The LINK can be in low power states[L0s and L1] when send LTR Message is trigered. So, the user has to consider the exit latencies while programming this field. It is recommended to program this field with about 2 us higher than the required interval to account for the L0s/L1 exit latencies.
